# GD32W515Tx register map
File version: 1.0
CPU: CM33 r0p0, little endian, MPU, FPU, 4 interrupt priority bits
Registers are 32-bit, read-write, reset 0x0 unless marked. A register's access mark holds for its fields unless they carry their own. Offsets are from the block's base; [hi:lo] are bit positions; {n}, {i} and the like mark numbered series.

## TIMER5 — Basic-timers
Base 0x40001000
Same registers: SEC_TIMER5 0x50001000
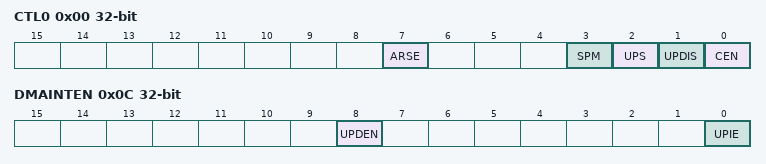
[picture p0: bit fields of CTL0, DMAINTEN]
0x00 CTL0 — control register 0
  [7] ARSE — Auto-reload preload enable
  [3] SPM — One-pulse mode
  [2] UPS — Update request source
  [1] UPDIS — Update disable
  [0] CEN — Counter enable
0x04 CTL1 — control register 1
  [6:4] MMC — Master mode selection
0x0C DMAINTEN — DMA/Interrupt enable register
  [8] UPDEN — Update DMA request enable
  [0] UPIE — Update interrupt enable
0x10 INTF — status register
  [0] UPIF — Update interrupt flag
0x14 SWEVG wo — event generation register
  [0] UPG — Update generation
0x24 CNT — counter
  [15:0] CNT — Low counter value
0x28 PSC — prescaler
  [15:0] PSC — Prescaler value
0x2C CAR — auto-reload register
  [15:0] CARL — Low Auto-reload value

## CAU — Cryptographic acceleration unit
Base 0x4C060000
Same registers: SEC_CAU 0x5C060000
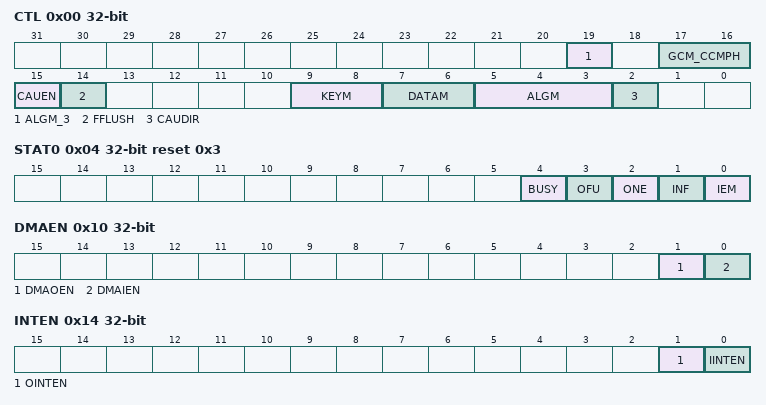
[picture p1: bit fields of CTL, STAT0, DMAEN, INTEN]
0x00 CTL access per field — CAU control register
  [19] ALGM_3 rw — Encryption/decryption algorithm mode bit 3
  [17:16] GCM_CCMPH rw — GCM CCM phase
  [15] CAUEN rw — Cryptographic module enable
  [14] FFLUSH wo — FIFO flush
  [9:8] KEYM rw — AES key size mode configuration
  [7:6] DATAM rw — Data swapping type mode configuration
  [5:3] ALGM rw — Encryption/decryption algorithm mode
  [2] CAUDIR rw — CAU direction
0x04 STAT0 ro reset 0x3 — CAU status register 0
  [4] BUSY — BUSY flag
  [3] OFU — OUT FIFO full flag
  [2] ONE — OUT FIFO not empty flag
  [1] INF — IN FIFO not full flag
  [0] IEM — IN FIFO empty flag
0x08 DI — CAU data input register
  [31:0] DI — Data input
0x0C DO ro — CAU data output register
  [31:0] DO — Data output
0x10 DMAEN — CAU DMA enable register
  [1] DMAOEN — Out FIFO DMA enable
  [0] DMAIEN — In FIFO DMA enable
0x14 INTEN — CAU interrupt enable register
  [1] OINTEN — Out FIFO interrupt enable
  [0] IINTEN — In FIFO interrupt enable
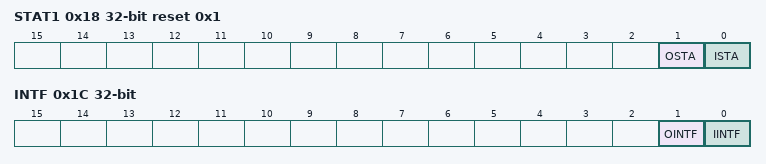
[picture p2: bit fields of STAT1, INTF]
0x18 STAT1 ro reset 0x1 — CAU interrupt status flag register 1
  [1] OSTA — Out FIFO interrupt flag
  [0] ISTA — In FIFO interrupt flag
0x1C INTF ro — CAU enable interrupt status flag register
  [1] OINTF — Out FIFO enabled interrupt flag
  [0] IINTF — In FIFO enabled interrupt flag
{0x20+8i} KEY{i}H wo (i=0..3) — CAU key register
  [31:0] KEY{i}H — Key for DES,TDES,AES
{0x24+8i} KEY{i}L wo (i=0..3) — CAU key register
  [31:0] KEY{i}L — Key for DES,TDES,AES
0x40 IV0H — CAU initialization register
  [31:0] IV0H — The initialization vector for DES,TDES,AES
0x44 IV0L — CAU initialization register
  [31:0] IV0L — The initialization vector for DES,TDES,AES
0x48 IV1H — CAU initialization register
  [31:0] IV1H — The initialization vector for DES,TDES,AES
0x4C IV1L — CAU initialization register
  [31:0] IV1L — The initialization vector for DES,TDES,AES

## PKCAU — Public Key Cryptographic Acceleration Unit
Base 0x4C061000
Same registers: SEC_PKCAU 0x5C061000
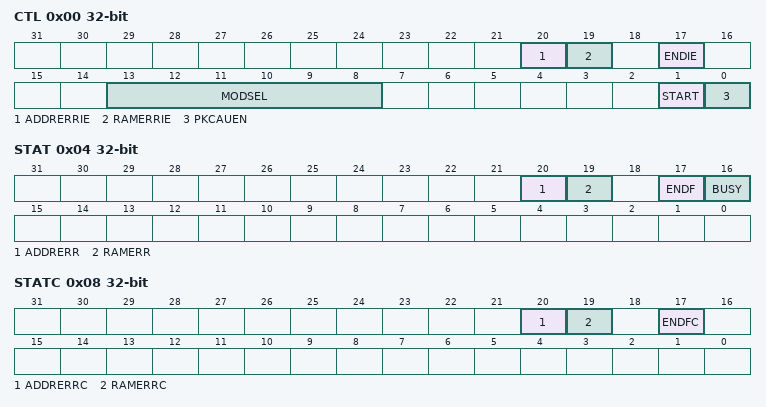
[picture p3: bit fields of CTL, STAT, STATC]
0x00 CTL — Control register
  [20] ADDRERRIE — Address error interrupt enable
  [19] RAMERRIE — RAM error interrupt enable
  [17] ENDIE — End of operation interrupt enable
  [13:8] MODSEL — PKCAU operation mode selection
  [1] START — PKCAU starts operation
  [0] PKCAUEN — PKCAU enable
0x04 STAT ro — Status register
  [20] ADDRERR — Address error
  [19] RAMERR — PKCAU RAM error
  [17] ENDF — End of PKCAU operation
  [16] BUSY — Busy flag
0x08 STATC wo — Status clear register
  [20] ADDRERRC — Address error flag clear
  [19] RAMERRC — PKCAU RAM error flag clear
  [17] ENDFC — End of PKCAU operation flag clear

## HAU — HAU acceleration unit
Base 0x4C060400
Same registers: SEC_HAU 0x5C060400
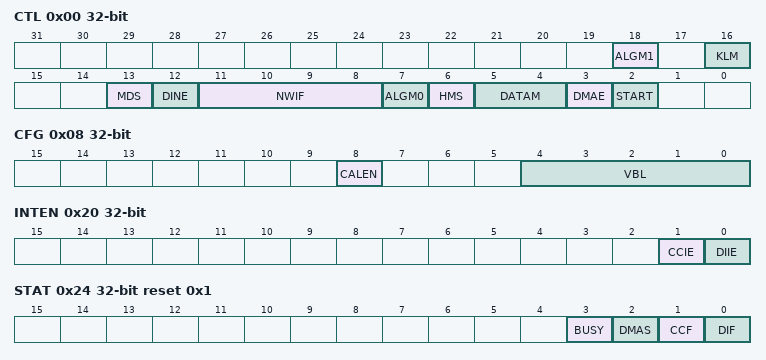
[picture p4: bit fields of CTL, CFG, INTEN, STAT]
0x00 CTL access per field — HAU control register
  [18] ALGM1 rw — Algorithm selection bit 1
  [16] KLM rw — Key length mode
  [13] MDS rw — Multiple DMA selection
  [12] DINE ro — DI register is not empty
  [11:8] NWIF ro — Number of words in IN FIFO
  [7] ALGM0 rw — Algorithm selection bit 0
  [6] HMS rw — HAU mode selection
  [5:4] DATAM rw — Data type mode
  [3] DMAE rw — DMA enable
  [2] START wo — Start message digest calculation
0x04 DI — HAU data input register
  [31:0] DI — Message data input
0x08 CFG access per field — HAU configuration register
  [8] CALEN wo — Digest calculation enable
  [4:0] VBL rw — Valid bits length in the last word
{0xC+4i} DO{i} ro (i=0..4) — HAU data output register
  [31:0] DO{i} — message digest result of hash algorithm
0x20 INTEN — HAU interrupt enable register
  [1] CCIE — calculation completion interrupt enable
  [0] DIIE — Data input interrupt enable
0x24 STAT ro reset 0x1 — HAU status and interrupt flag register
  [3] BUSY — Busy flag bit
  [2] DMAS — DMA status flag
  [1] CCF — Digest calculation completion flag
  [0] DIF — Data input flag
0xF8 CTXS0 reset 0x2 — Context switch register x
  [31:0] CTX0 — The complete internal status
{0xF8+4i} CTXS{i} (i=1..53) — Context switch register x
  [31:0] CTX{i} — The complete internal status
{0x310+4i} DO{i} ro (i=5..7) — HAU data output register
  [31:0] DO{i} — message digest result of hash algorithm
